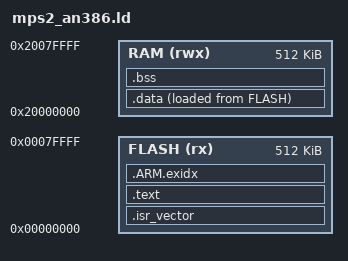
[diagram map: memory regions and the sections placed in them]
/* QEMU MPS2-AN386 (Cortex-M4): code in ZBT SSRAM1 at 0x00000000, data in the
 * SSRAM2/3 block at 0x20000000 (same map as examples/g2g-qemu/memory.x). */
MEMORY
{
  FLASH (rx)  : ORIGIN = 0x00000000, LENGTH = 512K
  RAM   (rwx) : ORIGIN = 0x20000000, LENGTH = 512K
}

ENTRY(Reset_Handler)

_estack = ORIGIN(RAM) + LENGTH(RAM);

SECTIONS
{
  .isr_vector :
  {
    KEEP(*(.isr_vector))
  } > FLASH

  .text :
  {
    *(.text*)
    *(.rodata*)
    . = ALIGN(4);
  } > FLASH

  .ARM.exidx :
  {
    *(.ARM.exidx*)
  } > FLASH

  _sidata = LOADADDR(.data);

  .data :
  {
    . = ALIGN(4);
    _sdata = .;
    *(.data*)
    . = ALIGN(4);
    _edata = .;
  } > RAM AT> FLASH

  .bss :
  {
    . = ALIGN(4);
    _sbss = .;
    *(.bss*)
    *(COMMON)
    . = ALIGN(4);
    _ebss = .;
  } > RAM
}
